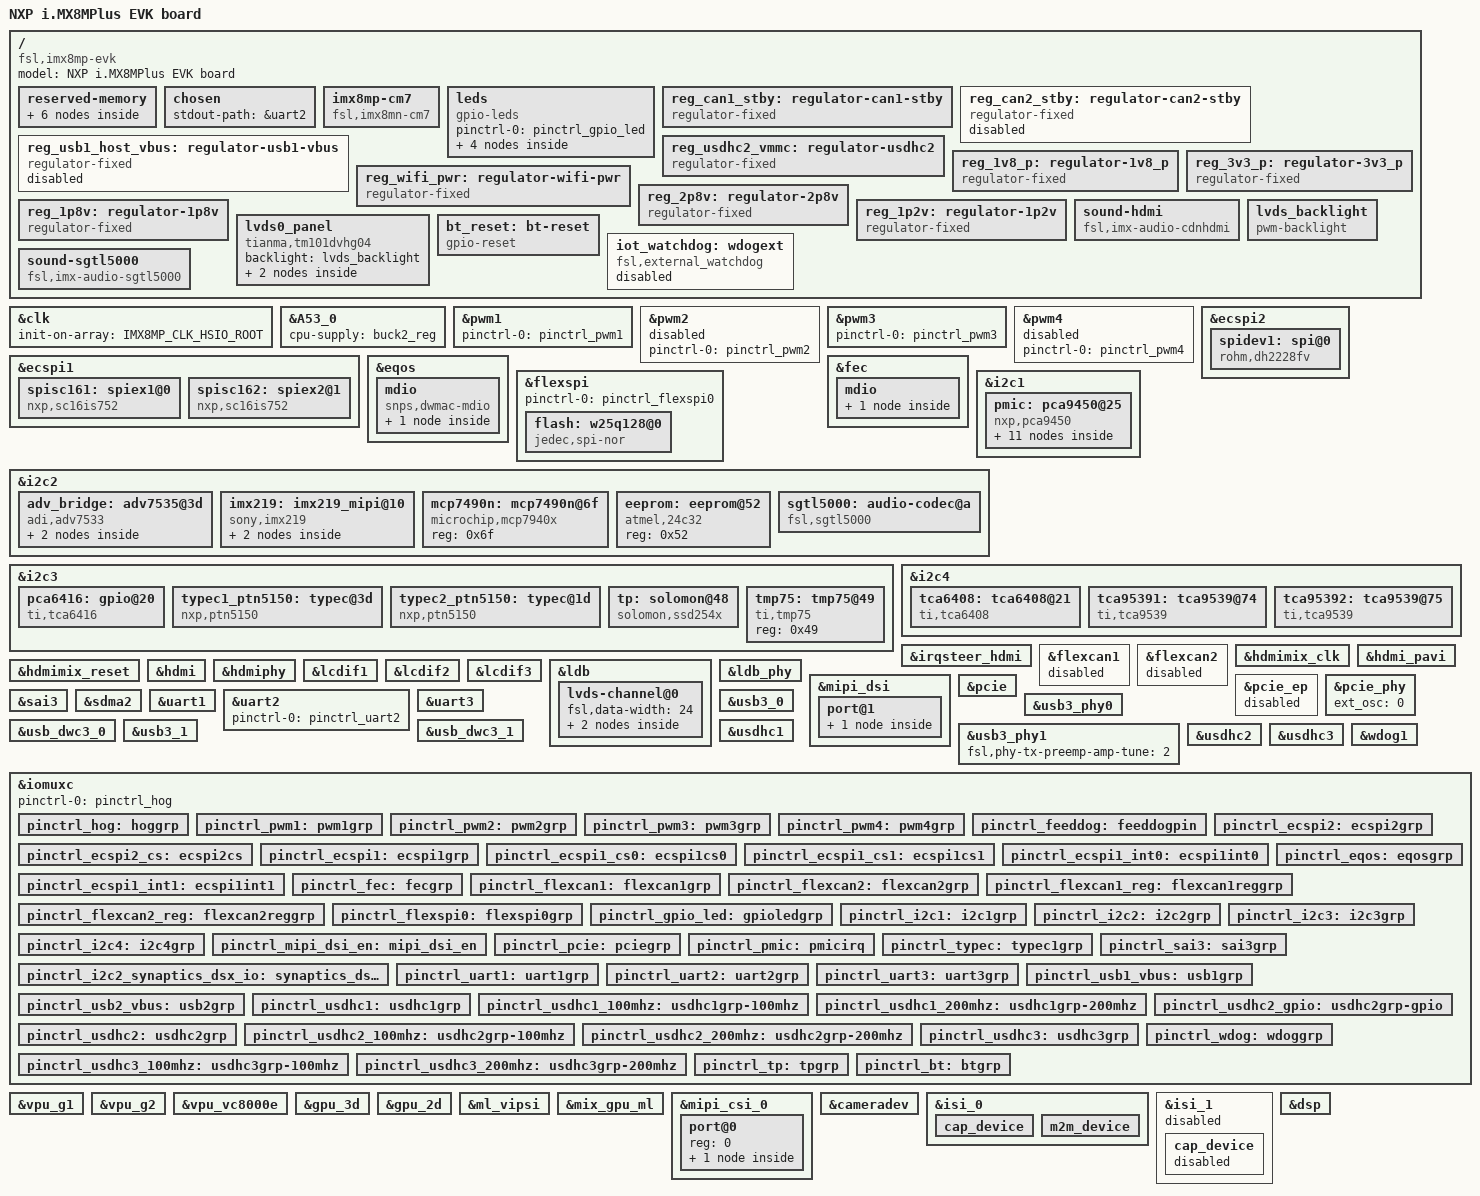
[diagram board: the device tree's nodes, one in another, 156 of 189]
// SPDX-License-Identifier: (GPL-2.0+ OR MIT)
/*
 * Copyright 2019 NXP
 */

/dts-v1/;

#include <dt-bindings/usb/pd.h>
#include "imx8mp-common.dtsi"

/ {
	model = "NXP i.MX8MPlus EVK board";
	compatible = "fsl,imx8mp-evk", "fsl,imx8mp";

	reserved-memory {
		#address-cells = <2>;
		#size-cells = <2>;
		ranges;

		rpmsg_reserved: rpmsg@0x55800000 {
			no-map;
			reg = <0 0x55800000 0 0x800000>;
		};

		m7_reserved: m7@0x80000000 {
			no-map;
			reg = <0 0x80000000 0 0x1000000>;
		};

		vdev0vring0: vdev0vring0@55000000 {
			compatible = "shared-dma-pool";
			reg = <0 0x55000000 0 0x8000>;
			no-map;
		};

		vdev0vring1: vdev0vring1@55008000 {
			compatible = "shared-dma-pool";
			reg = <0 0x55008000 0 0x8000>;
			no-map;
		};

		vdevbuffer: vdevbuffer@55400000 {
			compatible = "shared-dma-pool";
			reg = <0 0x55400000 0 0x100000>;
			no-map;
		};

		rsc-table {
			reg = <0 0x550ff000 0 0x1000>;
			no-map;
		};
	};

	chosen {
		stdout-path = &uart2;
	};

	imx8mp-cm7 {
		compatible = "fsl,imx8mn-cm7";
		rsc-da = <0x55000000>;
		clocks = <&clk IMX8MP_CLK_M7_DIV>;
		mbox-names = "tx", "rx", "rxdb";
		mboxes = <&mu 0 1
			  &mu 1 1
			  &mu 3 1>;
		memory-region = <&vdev0vring0>, <&vdev0vring1>, <&vdevbuffer>;
		status = "okay";
	};

	leds {
		compatible = "gpio-leds";
		pinctrl-names = "default";
		pinctrl-0 = <&pinctrl_gpio_led>;

		status {
			label = "status";
			gpios = <&gpio3 16 GPIO_ACTIVE_HIGH>;
			default-state = "off"; 
		};

		screen-vertical {
			label = "ScreenVertical";
			gpios = <&tca95392 1 GPIO_ACTIVE_LOW>;
			default-state = "on";
		};

		screen-horizontal {
			label = "ScreenHorizontal";
			gpios = <&tca95392 2 GPIO_ACTIVE_HIGH>;
			default-state = "on";
		};

		csi-gpio {
			label = "CSI_GPIO";
			gpios = <&tca95392 11 GPIO_ACTIVE_HIGH>;
			default-state = "on";
		};
	};

	reg_can1_stby: regulator-can1-stby {
		compatible = "regulator-fixed";
		regulator-name = "can1-stby";
		pinctrl-names = "default";
		pinctrl-0 = <&pinctrl_flexcan1_reg>;
		regulator-min-microvolt = <3300000>;
		regulator-max-microvolt = <3300000>;
		gpio = <&gpio5 5 GPIO_ACTIVE_HIGH>;
		enable-active-high;
	};

	reg_can2_stby: regulator-can2-stby {
		compatible = "regulator-fixed";
		regulator-name = "can2-stby";
		pinctrl-names = "default";
		pinctrl-0 = <&pinctrl_flexcan2_reg>;
		regulator-min-microvolt = <3300000>;
		regulator-max-microvolt = <3300000>;
		gpio = <&gpio4 27 GPIO_ACTIVE_HIGH>;
		enable-active-high;
	        status = "disable";
	};

	reg_usb1_host_vbus: regulator-usb1-vbus {
		compatible = "regulator-fixed";
		regulator-name = "usb1_host_vbus";
		pinctrl-names = "default";
		pinctrl-0 = <&pinctrl_usb1_vbus>;
		regulator-min-microvolt = <5000000>;
		regulator-max-microvolt = <5000000>;
		gpio = <&gpio1 14 GPIO_ACTIVE_HIGH>;
		enable-active-high;
		regulator-always-on;
	        status = "disable";
	};

	reg_usdhc2_vmmc: regulator-usdhc2 {
		compatible = "regulator-fixed";
		regulator-name = "VSD_3V3";
		regulator-min-microvolt = <3300000>;
		regulator-max-microvolt = <3300000>;
		gpio = <&gpio2 19 GPIO_ACTIVE_HIGH>;
		enable-active-high;
		startup-delay-us = <100>;
		off-on-delay-us = <12000>;
	};

	reg_1v8_p: regulator-1v8_p {
		compatible = "regulator-fixed";
		regulator-name = "vddd_1v8";
		regulator-min-microvolt = <1800000>;
		regulator-max-microvolt = <1800000>;
	};

	reg_3v3_p: regulator-3v3_p {
		compatible = "regulator-fixed";
		regulator-name = "vddio_vdda_3v3";
 		regulator-min-microvolt = <3300000>;
 		regulator-max-microvolt = <3300000>;
	};

        reg_wifi_pwr: regulator-wifi-pwr {
                compatible = "regulator-fixed";
                regulator-name = "wifi-pwr";
                regulator-min-microvolt = <3300000>;
                regulator-max-microvolt = <3300000>;
                gpio = <&gpio3 24 GPIO_ACTIVE_HIGH>;
                enable-active-high;
                regulator-always-on;
                startup-delay-us = <10000>;
                off-on-delay-us = <12000>;
        };

        reg_2p8v: regulator-2p8v {
                compatible = "regulator-fixed";
                regulator-name = "imx219_vana";
                regulator-min-microvolt = <2800000>;
                regulator-max-microvolt = <2800000>;
        };

        reg_1p8v: regulator-1p8v {
                compatible = "regulator-fixed";
                regulator-name = "imx219_vdig";
                regulator-min-microvolt = <1800000>;
                regulator-max-microvolt = <1800000>;
        };

        reg_1p2v: regulator-1p2v {
                compatible = "regulator-fixed";
                regulator-name = "imx219_vddl";
                regulator-min-microvolt = <1200000>;
                regulator-max-microvolt = <1200000>;
        };

	sound-hdmi {
		compatible = "fsl,imx-audio-cdnhdmi";
		model = "audio-hdmi";
		audio-cpu = <&aud2htx>;
		hdmi-out;
		constraint-rate = <44100>,
				<88200>,
				<176400>,
				<32000>,
				<48000>,
				<96000>,
				<192000>;
		status = "okay";
	};

	lvds_backlight: lvds_backlight {
		compatible = "pwm-backlight";
		pwms = <&pwm1 0 100000>;
		status = "okay";

		brightness-levels = < 0  1  2  3  4  5  6  7  8  9
				     10 11 12 13 14 15 16 17 18 19
				     20 21 22 23 24 25 26 27 28 29
				     30 31 32 33 34 35 36 37 38 39
				     40 41 42 43 44 45 46 47 48 49
				     50 51 52 53 54 55 56 57 58 59
				     60 61 62 63 64 65 66 67 68 69
				     70 71 72 73 74 75 76 77 78 79
				     80 81 82 83 84 85 86 87 88 89
				     90 91 92 93 94 95 96 97 98 99
				    100>;
		default-brightness-level = <80>;
	};

	lvds0_panel {
		compatible = "tianma,tm101dvhg04";
		backlight = <&lvds_backlight>;
		port {
			panel_lvds_in: endpoint {
				remote-endpoint = <&lvds_out>;
			};
		};
	};

	bt_reset: bt-reset {
		compatible = "gpio-reset";
		reset-gpios = <&gpio3 25 GPIO_ACTIVE_LOW>;
		reset-delay-us = <1000>;
		#reset-cells = <0>;
	};

        iot_watchdog: wdogext {
                pinctrl-names = "default";
                pinctrl-0 = <&pinctrl_feeddog>;
                compatible = "fsl,external_watchdog";
                wdt-in = <&gpio1 0 GPIO_ACTIVE_LOW>;
                wdt-feed-interval = <20>;
                //status = "okay";
                status = "disabled";
        };

	sound-sgtl5000 {
		compatible = "fsl,imx-audio-sgtl5000";
		model = "imx6ul-sgtl5000";
		audio-cpu = <&sai3>;
		audio-codec = <&sgtl5000>;
		audio-routing =
			"MIC_IN", "Mic Jack",
			"Mic Jack", "Mic Bias",
			"Headphone Jack", "HP_OUT";
		status = "okay";
	};

};

&clk {
	init-on-array = <IMX8MP_CLK_HSIO_ROOT>;
};

&A53_0 {
	cpu-supply = <&buck2_reg>;
};

&pwm1 {
	pinctrl-names = "default";
	pinctrl-0 = <&pinctrl_pwm1>;
	status = "okay";
};

&pwm2 {
	pinctrl-names = "default";
	pinctrl-0 = <&pinctrl_pwm2>;
	//status = "okay";
	status = "disabled";
};

/* Beeper */
&pwm3 {
        pinctrl-names = "default";
        pinctrl-0 = <&pinctrl_pwm3>;
        status = "okay";
};

&pwm4 {
	pinctrl-names = "default";
	pinctrl-0 = <&pinctrl_pwm4>;
	//status = "okay";
	status = "disabled";
};


&ecspi2 {
	#address-cells = <1>;
	#size-cells = <0>;
	fsl,spi-num-chipselects = <1>;
	pinctrl-names = "default";
	pinctrl-0 = <&pinctrl_ecspi2 &pinctrl_ecspi2_cs>;
	cs-gpios = <&gpio5 13 GPIO_ACTIVE_LOW>;
	status = "okay";

	spidev1: spi@0 {
		reg = <0>;
		compatible = "rohm,dh2228fv";
		spi-max-frequency = <500000>;
	};
};

&ecspi1 {
	#address-cells = <1>;
	#size-cells = <0>;
	fsl,spi-num-chipselects = <2>;
	pinctrl-names = "default";
	pinctrl-0 = <&pinctrl_ecspi1 &pinctrl_ecspi1_cs0 &pinctrl_ecspi1_int0
                     &pinctrl_ecspi1_int1 &pinctrl_ecspi1_cs1>;
	cs-gpios = <&gpio5 9 GPIO_ACTIVE_LOW
                    &gpio1 1 GPIO_ACTIVE_LOW>;
	status = "ok";

	spisc161: spiex1@0 {
		reg = <0>;
		compatible = "nxp,sc16is752";
		interrupt-parent = <&gpio4>;
		interrupts = <0 IRQ_TYPE_EDGE_FALLING>;
                clock-frequency = <14745600>;
		spi-max-frequency = <2000000>;
	};
	spisc162: spiex2@1 {
		reg = <1>;
		compatible = "nxp,sc16is752";
		interrupt-parent = <&gpio4>;
		interrupts = <19 IRQ_TYPE_EDGE_FALLING>;
                clock-frequency = <14745600>;
		spi-max-frequency = <2000000>;
	};
};

&eqos {
	pinctrl-names = "default";
	pinctrl-0 = <&pinctrl_eqos>;
	phy-mode = "rgmii-id";
	phy-handle = <&ethphy0>;
	status = "okay";

	mdio {
		compatible = "snps,dwmac-mdio";
		#address-cells = <1>;
		#size-cells = <0>;

		ethphy0: ethernet-phy@2 {
			compatible = "ethernet-phy-ieee802.3-c22";
			reg = <2>;
			micrel,led-mode = <1>;
                        eee-broken-100tx;
                        eee-broken-1000t;
                        enable-10bt-preamble;
		};
	};
};

&fec {
	pinctrl-names = "default";
	pinctrl-0 = <&pinctrl_fec>;
	phy-mode = "rgmii-id";
	phy-handle = <&ethphy1>;
	fsl,magic-packet;
	status = "okay";

	mdio {
		#address-cells = <1>;
		#size-cells = <0>;

		ethphy1: ethernet-phy@1 {
			compatible = "ethernet-phy-ieee802.3-c22";
			reg = <1>;
			micrel,led-mode = <1>;
                        eee-broken-100tx;
                        eee-broken-1000t;
		};
	};
};

&flexspi {
	pinctrl-names = "default";
	pinctrl-0 = <&pinctrl_flexspi0>;
	status = "okay";

	/*	Winbond 25Q128JWSIQ SPI NOR flash	*/
	flash: w25q128@0 {
		#address-cells = <1>;
		#size-cells = <1>;
		compatible = "jedec,spi-nor";
		m25p,fast-read;
		spi-tx-bus-width = <1>;
		spi-rx-bus-width = <4>;
		spi-max-frequency = <40000000>;
		reg = <0>;
		status = "okay";
	};
};

&i2c1 {
	clock-frequency = <100000>;
	pinctrl-names = "default";
	pinctrl-0 = <&pinctrl_i2c1>;
	status = "okay";

	pmic: pca9450@25 {
		reg = <0x25>;
		compatible = "nxp,pca9450";
		/* PMIC PCA9450 PMIC_nINT GPIO1_IO3 */
		pinctrl-0 = <&pinctrl_pmic>;
		gpio_intr = <&gpio1 3 GPIO_ACTIVE_LOW>;

		regulators {
			#address-cells = <1>;
			#size-cells = <0>;

			pca9450,pmic-buck2-uses-i2c-dvs;
			/* Run/Standby voltage */
			pca9450,pmic-buck2-dvs-voltage = <950000>, <850000>;

			buck1_reg: regulator@0 {
				reg = <0>;
				regulator-compatible = "buck1";
				regulator-min-microvolt = <600000>;
				regulator-max-microvolt = <2187500>;
				regulator-boot-on;
				regulator-always-on;
				regulator-ramp-delay = <3125>;
			};

			buck2_reg: regulator@1 {
				reg = <1>;
				regulator-compatible = "buck2";
				regulator-min-microvolt = <600000>;
				regulator-max-microvolt = <2187500>;
				regulator-boot-on;
				regulator-always-on;
				regulator-ramp-delay = <3125>;
			};

			buck4_reg: regulator@3 {
				reg = <3>;
				regulator-compatible = "buck4";
				regulator-min-microvolt = <600000>;
				regulator-max-microvolt = <3400000>;
				regulator-boot-on;
				regulator-always-on;
			};

			buck5_reg: regulator@4 {
				reg = <4>;
				regulator-compatible = "buck5";
				regulator-min-microvolt = <600000>;
				regulator-max-microvolt = <3400000>;
				regulator-boot-on;
				regulator-always-on;
			};

			buck6_reg: regulator@5 {
				reg = <5>;
				regulator-compatible = "buck6";
				regulator-min-microvolt = <600000>;
				regulator-max-microvolt = <3400000>;
				regulator-boot-on;
				regulator-always-on;
			};

			ldo1_reg: regulator@6 {
				reg = <6>;
				regulator-compatible = "ldo1";
				regulator-min-microvolt = <1600000>;
				regulator-max-microvolt = <3300000>;
				regulator-boot-on;
				regulator-always-on;
			};

			ldo2_reg: regulator@7 {
				reg = <7>;
				regulator-compatible = "ldo2";
				regulator-min-microvolt = <800000>;
				regulator-max-microvolt = <1150000>;
				regulator-boot-on;
				regulator-always-on;
			};

			ldo3_reg: regulator@8 {
				reg = <8>;
				regulator-compatible = "ldo3";
				regulator-min-microvolt = <800000>;
				regulator-max-microvolt = <3300000>;
				regulator-boot-on;
				regulator-always-on;
			};

			ldo4_reg: regulator@9 {
				reg = <9>;
				regulator-compatible = "ldo4";
				regulator-min-microvolt = <800000>;
				regulator-max-microvolt = <3300000>;
				regulator-boot-on;
				regulator-always-on;
			};

			ldo5_reg: regulator@10 {
				reg = <10>;
				regulator-compatible = "ldo5";
				regulator-min-microvolt = <1800000>;
				regulator-max-microvolt = <3300000>;
			};
		};
	};
};


&i2c2 {
	clock-frequency = <100000>;
	pinctrl-names = "default";
	pinctrl-0 = <&pinctrl_i2c2>;
	status = "okay";

	adv_bridge: adv7535@3d {
		compatible = "adi,adv7533";
		reg = <0x3d>;
		adi,addr-cec = <0x3b>;
		adi,dsi-lanes = <4>;
		status = "okay";

		port {
			adv7535_from_dsim: endpoint {
				remote-endpoint = <&dsim_to_adv7535>;
			};
		};
	};

        imx219: imx219_mipi@10 {
		status = "okay";
		compatible = "sony,imx219";
		reg = <0x10>;
		//rotation = <180>;
                clocks = <&clk IMX8MP_CLK_IPP_DO_CLKO2>;
                clock-names = "xclk";
                assigned-clocks = <&clk IMX8MP_CLK_IPP_DO_CLKO2>;
                assigned-clock-parents = <&clk IMX8MP_CLK_24M>;
                assigned-clock-rates = <24000000>;

		VANA-supply = <&reg_2p8v>;      /* 2.8v */
		VDIG-supply = <&reg_1p8v>;   /* 1.8v */
		VDDL-supply = <&reg_1p2v>;   /* 1.2v */

		port {
			imx219_0_ep: endpoint {
				remote-endpoint = <&mipi_csi0_ep>;
				data-lanes = <1 2>;
				clock-lanes = <0>;
				// TBD for below properties
				clock-noncontinuous;
				link-frequencies = /bits/ 64 <456000000>;
			};
		};
	};

	mcp7490n: mcp7490n@6f {
		compatible = "microchip,mcp7940x";
		reg = <0x6f>;
		status = "okay";
	};

	/*	EEPROM CHIP 24AA32A-I/SN	*/
	eeprom: eeprom@52 {
		compatible = "atmel,24c32";
		reg = <0x52>;
		status = "okay";
	};

	sgtl5000: audio-codec@a {
		compatible = "fsl,sgtl5000";
		reg = <0x0a>;
		clocks = <&audiomix_clk IMX8MP_CLK_AUDIOMIX_SAI3_MCLK1>;
		clock-names = "mclk";
		VDDD-supply = <&reg_1v8_p>;
		VDDIO-supply = <&reg_1v8_p>;
		VDDA-supply = <&reg_3v3_p>;
		status = "okay";
	};

};

&i2c3 {
	clock-frequency = <100000>;
	pinctrl-names = "default";
	pinctrl-0 = <&pinctrl_i2c3>;
	status = "okay";

	pca6416: gpio@20 {
		compatible = "ti,tca6416";
		reg = <0x20>;
		gpio-controller;
		#gpio-cells = <2>;
	};

	typec1_ptn5150: typec@3d {
		compatible = "nxp,ptn5150";
		reg = <0x3d>;
                pinctrl-names = "default";
	        pinctrl-0 = <&pinctrl_usb1_vbus>;
		//connect-gpios = <&gpio1 11 GPIO_ACTIVE_HIGH>;
		vbus-gpios = <&gpio1 11 GPIO_ACTIVE_HIGH>;
	};

	typec2_ptn5150: typec@1d {
		compatible = "nxp,ptn5150";
		reg = <0x1d>;
                pinctrl-names = "default";
	        pinctrl-0 = <&pinctrl_usb2_vbus>;
		//connect-gpios = <&gpio1 14 GPIO_ACTIVE_HIGH>;
		vbus-gpios = <&gpio1 14 GPIO_ACTIVE_HIGH>;
	};

	tp: solomon@48 {
		compatible = "solomon,ssd254x";
		pinctrl-names = "default";
		pinctrl-0 = <&pinctrl_tp>;
		reg = <0x48>;
		gpios = <&gpio4 27 1>, /* interrupt */
		<&tca95392 0 1>; /* Reset */
	};

	/*	temperature sensor	*/
	tmp75: tmp75@49 {
		compatible = "ti,tmp75";
		reg = <0x49>;
		status = "okay";
	};
};

&i2c4 {
        clock-frequency = <100000>;
        pinctrl-names = "default";
        pinctrl-0 = <&pinctrl_i2c4>;
        status = "okay";

        tca6408: tca6408@21 {
                compatible = "ti,tca6408";
                reg = <0x21>;
                #gpio-cells = <2>;
                gpio-controller;
        };

        tca95391: tca9539@74 {
                compatible = "ti,tca9539";
                reg = <0x74>;
                #gpio-cells = <2>;
                gpio-controller;
        };

        tca95392: tca9539@75 {
                compatible = "ti,tca9539";
                reg = <0x75>;
                #gpio-cells = <2>;
                gpio-controller;
        };
};

&irqsteer_hdmi {
	status = "okay";
};

&flexcan1 {
	pinctrl-names = "default";
	pinctrl-0 = <&pinctrl_flexcan1>;
	xceiver-supply = <&reg_can1_stby>;
	status = "disabled";
};

&flexcan2 {
	pinctrl-names = "default";
	pinctrl-0 = <&pinctrl_flexcan2>;
	xceiver-supply = <&reg_can2_stby>;
	pinctrl-assert-gpios = <&pca6416 3 GPIO_ACTIVE_HIGH>;
	status = "disabled";/* can2 pin conflict with pdm: gpio low select pdm, gpio high select can2 */
};

&hdmimix_clk {
	status = "okay";
};

&hdmimix_reset {
	status = "okay";
};

&hdmi_pavi {
	status = "okay";
};

&hdmi {
	status = "okay";
};

&hdmiphy {
	status = "okay";
};

&lcdif1 {
	status = "okay";
};

&lcdif2 {
	status = "okay";
};

&lcdif3 {
	status = "okay";

	thres-low  = <1 2>;             /* (FIFO * 1 / 2) */
	thres-high = <3 4>;             /* (FIFO * 3 / 4) */
};

&ldb {
	status = "okay";

	lvds-channel@0 {
		fsl,data-width = <24>;
		status = "okay";

		port@1 {
			reg = <1>;

			lvds_out: endpoint {
				remote-endpoint = <&panel_lvds_in>;
			};
		};
	};
};

&ldb_phy {
	status = "okay";
};

&mipi_dsi {
	status = "okay";

	port@1 {
		dsim_to_adv7535: endpoint {
			remote-endpoint = <&adv7535_from_dsim>;
			attach-bridge;
		};
	};
};

&pcie{
	pinctrl-names = "default";
	pinctrl-0 = <&pinctrl_pcie>;
	disable-gpio = <&gpio4 20 GPIO_ACTIVE_LOW>;
	reset-gpio = <&gpio4 18 GPIO_ACTIVE_LOW>;
	ext_osc = <0>;
	clocks = <&clk IMX8MP_CLK_HSIO_AXI_DIV>,
		 <&clk IMX8MP_CLK_PCIE_AUX>,
		 <&clk IMX8MP_CLK_DUMMY>,
		 <&clk IMX8MP_CLK_PCIE_ROOT>;
	clock-names = "pcie", "pcie_aux", "pcie_phy", "pcie_bus";
	assigned-clocks = <&clk IMX8MP_CLK_HSIO_AXI_SRC>,
			  <&clk IMX8MP_CLK_PCIE_AUX>;
	assigned-clock-rates = <500000000>, <10000000>;
	assigned-clock-parents = <&clk IMX8MP_SYS_PLL2_500M>,
				 <&clk IMX8MP_SYS_PLL2_50M>;
	l1ss-disabled;
	status = "okay";
};

&pcie_ep{
	pinctrl-names = "default";
	pinctrl-0 = <&pinctrl_pcie>;
	ext_osc = <1>;
	clocks = <&clk IMX8MP_CLK_HSIO_AXI_DIV>,
		 <&clk IMX8MP_CLK_PCIE_AUX>,
		 <&clk IMX8MP_CLK_DUMMY>,
		 <&clk IMX8MP_CLK_PCIE_ROOT>;
	clock-names = "pcie", "pcie_aux", "pcie_phy", "pcie_bus";
	assigned-clocks = <&clk IMX8MP_CLK_HSIO_AXI_SRC>,
			  <&clk IMX8MP_CLK_PCIE_AUX>;
	assigned-clock-rates = <500000000>, <10000000>;
	assigned-clock-parents = <&clk IMX8MP_SYS_PLL2_500M>,
				 <&clk IMX8MP_SYS_PLL2_50M>;
	status = "disabled";
};

&pcie_phy{
	ext_osc = <0>;
	status = "okay";
};

&sai3 {
	pinctrl-names = "default";
	pinctrl-0 = <&pinctrl_sai3>;
	assigned-clocks = <&clk IMX8MP_CLK_SAI3>;
	assigned-clock-parents = <&clk IMX8MP_AUDIO_PLL1_OUT>;
	assigned-clock-rates = <12288000>;
	clocks = <&audiomix_clk IMX8MP_CLK_AUDIOMIX_SAI3_IPG>, <&clk IMX8MP_CLK_DUMMY>,
		 <&audiomix_clk IMX8MP_CLK_AUDIOMIX_SAI3_MCLK1>, <&clk IMX8MP_CLK_DUMMY>,
		 <&clk IMX8MP_CLK_DUMMY>;
	clock-names = "bus", "mclk0", "mclk1", "mclk2", "mclk3";
	fsl,sai-mclk-direction-output;
	status = "okay";
};

&sdma2 {
	status = "okay";
};

&uart1 { /* BT */
	pinctrl-names = "default";
	pinctrl-0 = <&pinctrl_uart1
			&pinctrl_bt>;
	assigned-clocks = <&clk IMX8MP_CLK_UART1>;
	assigned-clock-parents = <&clk IMX8MP_SYS_PLL1_80M>;
	fsl,uart-has-rtscts;
	resets = <&bt_reset>;
	status = "okay";
};

&uart2 {
	/* console */
	pinctrl-names = "default";
	pinctrl-0 = <&pinctrl_uart2>;
	status = "okay";
};

&uart3 {
	pinctrl-names = "default";
	pinctrl-0 = <&pinctrl_uart3>;
	assigned-clocks = <&clk IMX8MP_CLK_UART3>;
	assigned-clock-parents = <&clk IMX8MP_SYS_PLL1_80M>;
	fsl,uart-has-rtscts;
	status = "okay";
	//status = "disable";
};

&usb3_phy0 {
	//vbus-power-supply = <&typec1_ptn5150>;
	fsl,phy-tx-vref-tune = <6>;
	fsl,phy-tx-rise-tune = <0>;
	fsl,phy-tx-preemp-amp-tune = <3>;
	fsl,phy-comp-dis-tune = <7>;
	fsl,pcs-tx-deemph-3p5db = <0x21>;
	fsl,phy-pcs-tx-swing-full = <0x7f>;
	status = "okay";
};

&usb3_0 {
	status = "okay";
};

&usb_dwc3_0 {
	//dr_mode = "peripheral";
	dr_mode = "otg";
	extcon = <&typec1_ptn5150>;
	hnp-disable;
	srp-disable;
	adp-disable;
	//usb-role-switch;
	status = "okay";
};

&usb3_phy1 {
	fsl,phy-tx-preemp-amp-tune = <2>;
	status = "okay";
};

&usb3_1 {
	status = "okay";
};

&usb_dwc3_1 {
	//dr_mode = "peripheral";
        dr_mode = "otg";
	extcon = <&typec2_ptn5150>;
        hnp-disable;
        srp-disable;
        adp-disable;
        //usb-role-switch;
        status = "okay";
};

&usdhc1 {
	pinctrl-names = "default", "state_100mhz", "state_200mhz";
	pinctrl-0 = <&pinctrl_usdhc1>;
	pinctrl-1 = <&pinctrl_usdhc1_100mhz>;
	pinctrl-2 = <&pinctrl_usdhc1_200mhz>;
	bus-width = <4>;
        vmmc-supply = <&reg_wifi_pwr>;
	non-removable;
	keep-power-in-suspend;
	enable-sdio-wakeup;
	status = "okay";
};

&usdhc2 {
	pinctrl-names = "default", "state_100mhz", "state_200mhz";
	pinctrl-0 = <&pinctrl_usdhc2>, <&pinctrl_usdhc2_gpio>;
	pinctrl-1 = <&pinctrl_usdhc2_100mhz>, <&pinctrl_usdhc2_gpio>;
	pinctrl-2 = <&pinctrl_usdhc2_200mhz>, <&pinctrl_usdhc2_gpio>;
	cd-gpios = <&gpio2 12 GPIO_ACTIVE_LOW>;
	vmmc-supply = <&reg_usdhc2_vmmc>;
	bus-width = <4>;
	status = "okay";
};

&usdhc3 {
	pinctrl-names = "default", "state_100mhz", "state_200mhz";
	pinctrl-0 = <&pinctrl_usdhc3>;
	pinctrl-1 = <&pinctrl_usdhc3_100mhz>;
	pinctrl-2 = <&pinctrl_usdhc3_200mhz>;
	bus-width = <8>;
	non-removable;
	status = "okay";
};

&wdog1 {
	pinctrl-names = "default";
	pinctrl-0 = <&pinctrl_wdog>;
	fsl,ext-reset-output;
	status = "okay";
};

&iomuxc {
	pinctrl-names = "default";
	pinctrl-0 = <&pinctrl_hog>;

	pinctrl_hog: hoggrp {
		fsl,pins = <
			MX8MP_IOMUXC_HDMI_DDC_SCL__HDMIMIX_HDMI_SCL	0x400001c3
			MX8MP_IOMUXC_HDMI_DDC_SDA__HDMIMIX_HDMI_SDA	0x400001c3
			MX8MP_IOMUXC_HDMI_HPD__HDMIMIX_HDMI_HPD		0x40000019
			MX8MP_IOMUXC_HDMI_CEC__HDMIMIX_HDMI_CEC		0x40000019
		>;
	};

	pinctrl_pwm1: pwm1grp {
		fsl,pins = <
			MX8MP_IOMUXC_GPIO1_IO08__PWM1_OUT	0x116
		>;
	};

	pinctrl_pwm2: pwm2grp {
		fsl,pins = <
			MX8MP_IOMUXC_GPIO1_IO11__PWM2_OUT	0x116
		>;
	};

        pinctrl_pwm3: pwm3grp {
                fsl,pins = <
                        MX8MP_IOMUXC_GPIO1_IO10__PWM3_OUT       0x116
                >;
        };

	pinctrl_pwm4: pwm4grp {
		fsl,pins = <
			MX8MP_IOMUXC_SAI5_RXFS__PWM4_OUT	0x116
		>;
	};

        pinctrl_feeddog: feeddogpin {
                fsl,pins = <
                        MX8MP_IOMUXC_GPIO1_IO00__GPIO1_IO00     0x16
                >;
        };

	pinctrl_ecspi2: ecspi2grp {
		fsl,pins = <
			MX8MP_IOMUXC_ECSPI2_SCLK__ECSPI2_SCLK		0x82
			MX8MP_IOMUXC_ECSPI2_MOSI__ECSPI2_MOSI		0x82
			MX8MP_IOMUXC_ECSPI2_MISO__ECSPI2_MISO		0x82
		>;
	};

	pinctrl_ecspi2_cs: ecspi2cs {
		fsl,pins = <
			MX8MP_IOMUXC_ECSPI2_SS0__GPIO5_IO13		0x40000
		>;
	};


	pinctrl_ecspi1: ecspi1grp {
		fsl,pins = <
			MX8MP_IOMUXC_ECSPI1_SCLK__ECSPI1_SCLK		0x82
			MX8MP_IOMUXC_ECSPI1_MOSI__ECSPI1_MOSI		0x82
			MX8MP_IOMUXC_ECSPI1_MISO__ECSPI1_MISO		0x82
		>;
	};

	pinctrl_ecspi1_cs0: ecspi1cs0 {
		fsl,pins = <
			MX8MP_IOMUXC_ECSPI1_SS0__GPIO5_IO09		0x40000
		>;
	};

	pinctrl_ecspi1_cs1: ecspi1cs1 {
		fsl,pins = <
			MX8MP_IOMUXC_GPIO1_IO01__GPIO1_IO01		0x19
		>;
	};

	pinctrl_ecspi1_int0: ecspi1int0 {
		fsl,pins = <
			MX8MP_IOMUXC_SAI1_RXFS__GPIO4_IO00		0x19
		>;
	};

	pinctrl_ecspi1_int1: ecspi1int1 {
		fsl,pins = <
                        MX8MP_IOMUXC_SAI1_TXD7__GPIO4_IO19	        0x19
		>;
	};

	pinctrl_eqos: eqosgrp {
		fsl,pins = <
			MX8MP_IOMUXC_ENET_MDC__ENET_QOS_MDC	                        0x3
			MX8MP_IOMUXC_ENET_MDIO__ENET_QOS_MDIO	                        0x3
			MX8MP_IOMUXC_ENET_RD0__ENET_QOS_RGMII_RD0	                0x91
			MX8MP_IOMUXC_ENET_RD1__ENET_QOS_RGMII_RD1	                0x91
			MX8MP_IOMUXC_ENET_RD2__ENET_QOS_RGMII_RD2	                0x91
			MX8MP_IOMUXC_ENET_RD3__ENET_QOS_RGMII_RD3	                0x91
			MX8MP_IOMUXC_ENET_RXC__CCM_ENET_QOS_CLOCK_GENERATE_RX_CLK	0x91
			MX8MP_IOMUXC_ENET_RX_CTL__ENET_QOS_RGMII_RX_CTL	                0x91
			MX8MP_IOMUXC_ENET_TD0__ENET_QOS_RGMII_TD0	        	0x91
			MX8MP_IOMUXC_ENET_TD1__ENET_QOS_RGMII_TD1	        	0x91
			MX8MP_IOMUXC_ENET_TD2__ENET_QOS_RGMII_TD2	        	0x91
			MX8MP_IOMUXC_ENET_TD3__ENET_QOS_RGMII_TD3	        	0x91
			MX8MP_IOMUXC_ENET_TX_CTL__ENET_QOS_RGMII_TX_CTL         	0x91
			MX8MP_IOMUXC_ENET_TXC__CCM_ENET_QOS_CLOCK_GENERATE_TX_CLK	0x91
			MX8MP_IOMUXC_SAI2_RXC__GPIO4_IO22		                0x19
		>;
	};

	pinctrl_fec: fecgrp {
		fsl,pins = <
			MX8MP_IOMUXC_SAI1_RXD2__ENET1_MDC		0x3
			MX8MP_IOMUXC_SAI1_RXD3__ENET1_MDIO		0x3
			MX8MP_IOMUXC_SAI1_RXD4__ENET1_RGMII_RD0		0x91
			MX8MP_IOMUXC_SAI1_RXD5__ENET1_RGMII_RD1		0x91
			MX8MP_IOMUXC_SAI1_RXD6__ENET1_RGMII_RD2		0x91
			MX8MP_IOMUXC_SAI1_RXD7__ENET1_RGMII_RD3		0x91
			MX8MP_IOMUXC_SAI1_TXC__ENET1_RGMII_RXC		0x91
			MX8MP_IOMUXC_SAI1_TXFS__ENET1_RGMII_RX_CTL	0x91
			MX8MP_IOMUXC_SAI1_TXD0__ENET1_RGMII_TD0		0x91
			MX8MP_IOMUXC_SAI1_TXD1__ENET1_RGMII_TD1		0x91
			MX8MP_IOMUXC_SAI1_TXD2__ENET1_RGMII_TD2		0x91
			MX8MP_IOMUXC_SAI1_TXD3__ENET1_RGMII_TD3		0x91
			MX8MP_IOMUXC_SAI1_TXD4__ENET1_RGMII_TX_CTL	0x91
			MX8MP_IOMUXC_SAI1_TXD5__ENET1_RGMII_TXC		0x91
			MX8MP_IOMUXC_SAI1_RXD0__GPIO4_IO02		0x19
		>;
	};

	pinctrl_flexcan1: flexcan1grp {
		fsl,pins = <
			MX8MP_IOMUXC_SPDIF_RX__CAN1_RX          0x154
			MX8MP_IOMUXC_SPDIF_TX__CAN1_TX          0x154
		>;
	};

	pinctrl_flexcan2: flexcan2grp {
		fsl,pins = <
			MX8MP_IOMUXC_SAI5_MCLK__CAN2_RX		0x154
			MX8MP_IOMUXC_SAI5_RXD3__CAN2_TX		0x154
		>;
	};

	pinctrl_flexcan1_reg: flexcan1reggrp {
		fsl,pins = <
			MX8MP_IOMUXC_SPDIF_EXT_CLK__GPIO5_IO05	0x154	/* CAN1_STBY */
		>;
	};

	pinctrl_flexcan2_reg: flexcan2reggrp {
		fsl,pins = <
			MX8MP_IOMUXC_SAI2_MCLK__GPIO4_IO27	0x154	/* CAN2_STBY */
		>;
	};

	pinctrl_flexspi0: flexspi0grp {
		fsl,pins = <
			MX8MP_IOMUXC_NAND_ALE__FLEXSPI_A_SCLK		0x1c2
			MX8MP_IOMUXC_NAND_CE0_B__FLEXSPI_A_SS0_B	0x82
			MX8MP_IOMUXC_NAND_DATA00__FLEXSPI_A_DATA00	0x82
			MX8MP_IOMUXC_NAND_DATA01__FLEXSPI_A_DATA01	0x82
			MX8MP_IOMUXC_NAND_DATA02__FLEXSPI_A_DATA02	0x82
			MX8MP_IOMUXC_NAND_DATA03__FLEXSPI_A_DATA03	0x82
		>;
	};

	pinctrl_gpio_led: gpioledgrp {
		fsl,pins = <
			MX8MP_IOMUXC_NAND_READY_B__GPIO3_IO16	0x19
		>;
	};

	pinctrl_i2c1: i2c1grp {
		fsl,pins = <
			MX8MP_IOMUXC_I2C1_SCL__I2C1_SCL		0x400001c3
			MX8MP_IOMUXC_I2C1_SDA__I2C1_SDA		0x400001c3
		>;
	};

	pinctrl_i2c2: i2c2grp {
		fsl,pins = <
			MX8MP_IOMUXC_I2C2_SCL__I2C2_SCL			0x400001c3
			MX8MP_IOMUXC_I2C2_SDA__I2C2_SDA			0x400001c3
		>;
	};

	pinctrl_i2c3: i2c3grp {
		fsl,pins = <
			MX8MP_IOMUXC_I2C3_SCL__I2C3_SCL			0x400001c3
			MX8MP_IOMUXC_I2C3_SDA__I2C3_SDA			0x400001c3
		>;
	};

	pinctrl_i2c4: i2c4grp {
		fsl,pins = <
			MX8MP_IOMUXC_I2C4_SCL__I2C4_SCL			0x400001c3
			MX8MP_IOMUXC_I2C4_SDA__I2C4_SDA			0x400001c3
		>;
	};

	pinctrl_mipi_dsi_en: mipi_dsi_en {
		fsl,pins = <
			MX8MP_IOMUXC_GPIO1_IO08__GPIO1_IO08	0x16
		>;
	};

	pinctrl_pcie: pciegrp {
		fsl,pins = <
			MX8MP_IOMUXC_SAI1_MCLK__GPIO4_IO20		0x41
			MX8MP_IOMUXC_SAI1_TXD6__GPIO4_IO18		0x41
		>;
	};

	pinctrl_pmic: pmicirq {
		fsl,pins = <
			MX8MP_IOMUXC_GPIO1_IO03__GPIO1_IO03	0x41
		>;
	};

	pinctrl_typec: typec1grp {
		fsl,pins = <
			MX8MP_IOMUXC_SAI1_TXD7__GPIO4_IO19	0x1c4
		>;
	};

	pinctrl_sai3: sai3grp {
		fsl,pins = <
			MX8MP_IOMUXC_SAI3_TXFS__AUDIOMIX_SAI3_TX_SYNC	0xd6
			MX8MP_IOMUXC_SAI3_TXC__AUDIOMIX_SAI3_TX_BCLK	0xd6
			MX8MP_IOMUXC_SAI3_RXD__AUDIOMIX_SAI3_RX_DATA00	0xd6
			MX8MP_IOMUXC_SAI3_TXD__AUDIOMIX_SAI3_TX_DATA00	0xd6
			MX8MP_IOMUXC_SAI3_MCLK__AUDIOMIX_SAI3_MCLK	0xd6
		>;
	};

	pinctrl_i2c2_synaptics_dsx_io: synaptics_dsx_iogrp {
		fsl,pins = <
			MX8MP_IOMUXC_GPIO1_IO09__GPIO1_IO09		0x16
		>;
	};

	pinctrl_uart1: uart1grp {
		fsl,pins = <
			MX8MP_IOMUXC_UART1_RXD__UART1_DCE_RX	0x140
			MX8MP_IOMUXC_UART1_TXD__UART1_DCE_TX	0x140
			MX8MP_IOMUXC_UART3_RXD__UART1_DCE_CTS	0x140
			MX8MP_IOMUXC_UART3_TXD__UART1_DCE_RTS	0x140
		>;
	};

	pinctrl_uart2: uart2grp {
		fsl,pins = <
			MX8MP_IOMUXC_UART2_RXD__UART2_DCE_RX	0x49
			MX8MP_IOMUXC_UART2_TXD__UART2_DCE_TX	0x49
		>;
	};

	pinctrl_uart3: uart3grp {
		fsl,pins = <
			MX8MP_IOMUXC_SD1_DATA6__UART3_DCE_TX 	0x49
			MX8MP_IOMUXC_SD1_DATA7__UART3_DCE_RX	0x49
		>;
	};

	pinctrl_usb1_vbus: usb1grp {
		fsl,pins = <
			MX8MP_IOMUXC_GPIO1_IO14__GPIO1_IO14	0x19
		>;
	};
	pinctrl_usb2_vbus: usb2grp {
		fsl,pins = <
			MX8MP_IOMUXC_GPIO1_IO11__GPIO1_IO11	0x19
		>;
	};

	pinctrl_usdhc1: usdhc1grp {
		fsl,pins = <
			MX8MP_IOMUXC_SD1_CLK__USDHC1_CLK	0x190
			MX8MP_IOMUXC_SD1_CMD__USDHC1_CMD	0x1d0
			MX8MP_IOMUXC_SD1_DATA0__USDHC1_DATA0	0x1d0
			MX8MP_IOMUXC_SD1_DATA1__USDHC1_DATA1	0x1d0
			MX8MP_IOMUXC_SD1_DATA2__USDHC1_DATA2	0x1d0
			MX8MP_IOMUXC_SD1_DATA3__USDHC1_DATA3	0x1d0
			MX8MP_IOMUXC_SAI5_RXD3__GPIO3_IO24      0x19
		>;
	};

	pinctrl_usdhc1_100mhz: usdhc1grp-100mhz {
		fsl,pins = <
			MX8MP_IOMUXC_SD1_CLK__USDHC1_CLK	0x194
			MX8MP_IOMUXC_SD1_CMD__USDHC1_CMD	0x1d4
			MX8MP_IOMUXC_SD1_DATA0__USDHC1_DATA0	0x1d4
			MX8MP_IOMUXC_SD1_DATA1__USDHC1_DATA1	0x1d4
			MX8MP_IOMUXC_SD1_DATA2__USDHC1_DATA2	0x1d4
			MX8MP_IOMUXC_SD1_DATA3__USDHC1_DATA3	0x1d4
			MX8MP_IOMUXC_SAI5_RXD3__GPIO3_IO24      0x19
		>;
	};

	pinctrl_usdhc1_200mhz: usdhc1grp-200mhz {
		fsl,pins = <
			MX8MP_IOMUXC_SD1_CLK__USDHC1_CLK	0x194
			MX8MP_IOMUXC_SD1_CMD__USDHC1_CMD	0x1d4
			MX8MP_IOMUXC_SD1_DATA0__USDHC1_DATA0	0x1d4
			MX8MP_IOMUXC_SD1_DATA1__USDHC1_DATA1	0x1d4
			MX8MP_IOMUXC_SD1_DATA2__USDHC1_DATA2	0x1d4
			MX8MP_IOMUXC_SD1_DATA3__USDHC1_DATA3	0x1d4
			MX8MP_IOMUXC_SAI5_RXD3__GPIO3_IO24      0x19
		>;
	};

	pinctrl_usdhc2_gpio: usdhc2grp-gpio {
		fsl,pins = <
			MX8MP_IOMUXC_SD2_CD_B__GPIO2_IO12 	0x1c4
			MX8MP_IOMUXC_SD2_RESET_B__GPIO2_IO19	0x41
		>;
	};

	pinctrl_usdhc2: usdhc2grp {
		fsl,pins = <
			MX8MP_IOMUXC_SD2_CLK__USDHC2_CLK	0x190
			MX8MP_IOMUXC_SD2_CMD__USDHC2_CMD	0x1d0
			MX8MP_IOMUXC_SD2_DATA0__USDHC2_DATA0	0x1d0
			MX8MP_IOMUXC_SD2_DATA1__USDHC2_DATA1	0x1d0
			MX8MP_IOMUXC_SD2_DATA2__USDHC2_DATA2	0x1d0
			MX8MP_IOMUXC_SD2_DATA3__USDHC2_DATA3	0x1d0
			MX8MP_IOMUXC_GPIO1_IO04__USDHC2_VSELECT	0xc1
		>;
	};

	pinctrl_usdhc2_100mhz: usdhc2grp-100mhz {
		fsl,pins = <
			MX8MP_IOMUXC_SD2_CLK__USDHC2_CLK	0x194
			MX8MP_IOMUXC_SD2_CMD__USDHC2_CMD	0x1d4
			MX8MP_IOMUXC_SD2_DATA0__USDHC2_DATA0	0x1d4
			MX8MP_IOMUXC_SD2_DATA1__USDHC2_DATA1	0x1d4
			MX8MP_IOMUXC_SD2_DATA2__USDHC2_DATA2	0x1d4
			MX8MP_IOMUXC_SD2_DATA3__USDHC2_DATA3	0x1d4
			MX8MP_IOMUXC_GPIO1_IO04__USDHC2_VSELECT 0xc1
		>;
	};

	pinctrl_usdhc2_200mhz: usdhc2grp-200mhz {
		fsl,pins = <
			MX8MP_IOMUXC_SD2_CLK__USDHC2_CLK	0x196
			MX8MP_IOMUXC_SD2_CMD__USDHC2_CMD	0x1d6
			MX8MP_IOMUXC_SD2_DATA0__USDHC2_DATA0	0x1d6
			MX8MP_IOMUXC_SD2_DATA1__USDHC2_DATA1	0x1d6
			MX8MP_IOMUXC_SD2_DATA2__USDHC2_DATA2	0x1d6
			MX8MP_IOMUXC_SD2_DATA3__USDHC2_DATA3	0x1d6
			MX8MP_IOMUXC_GPIO1_IO04__USDHC2_VSELECT 0xc1
		>;
	};

	pinctrl_usdhc3: usdhc3grp {
		fsl,pins = <
			MX8MP_IOMUXC_NAND_WE_B__USDHC3_CLK	0x190
			MX8MP_IOMUXC_NAND_WP_B__USDHC3_CMD	0x1d0
			MX8MP_IOMUXC_NAND_DATA04__USDHC3_DATA0	0x1d0
			MX8MP_IOMUXC_NAND_DATA05__USDHC3_DATA1	0x1d0
			MX8MP_IOMUXC_NAND_DATA06__USDHC3_DATA2	0x1d0
			MX8MP_IOMUXC_NAND_DATA07__USDHC3_DATA3	0x1d0
			MX8MP_IOMUXC_NAND_RE_B__USDHC3_DATA4	0x1d0
			MX8MP_IOMUXC_NAND_CE2_B__USDHC3_DATA5	0x1d0
			MX8MP_IOMUXC_NAND_CE3_B__USDHC3_DATA6	0x1d0
			MX8MP_IOMUXC_NAND_CLE__USDHC3_DATA7	0x1d0
			MX8MP_IOMUXC_NAND_CE1_B__USDHC3_STROBE	0x190
		>;
	};

	pinctrl_usdhc3_100mhz: usdhc3grp-100mhz {
		fsl,pins = <
			MX8MP_IOMUXC_NAND_WE_B__USDHC3_CLK	0x194
			MX8MP_IOMUXC_NAND_WP_B__USDHC3_CMD	0x1d4
			MX8MP_IOMUXC_NAND_DATA04__USDHC3_DATA0	0x1d4
			MX8MP_IOMUXC_NAND_DATA05__USDHC3_DATA1	0x1d4
			MX8MP_IOMUXC_NAND_DATA06__USDHC3_DATA2	0x1d4
			MX8MP_IOMUXC_NAND_DATA07__USDHC3_DATA3	0x1d4
			MX8MP_IOMUXC_NAND_RE_B__USDHC3_DATA4	0x1d4
			MX8MP_IOMUXC_NAND_CE2_B__USDHC3_DATA5	0x1d4
			MX8MP_IOMUXC_NAND_CE3_B__USDHC3_DATA6	0x1d4
			MX8MP_IOMUXC_NAND_CLE__USDHC3_DATA7	0x1d4
			MX8MP_IOMUXC_NAND_CE1_B__USDHC3_STROBE	0x194
		>;
	};

	pinctrl_usdhc3_200mhz: usdhc3grp-200mhz {
		fsl,pins = <
			MX8MP_IOMUXC_NAND_WE_B__USDHC3_CLK	0x196
			MX8MP_IOMUXC_NAND_WP_B__USDHC3_CMD	0x1d6
			MX8MP_IOMUXC_NAND_DATA04__USDHC3_DATA0	0x1d6
			MX8MP_IOMUXC_NAND_DATA05__USDHC3_DATA1	0x1d6
			MX8MP_IOMUXC_NAND_DATA06__USDHC3_DATA2	0x1d6
			MX8MP_IOMUXC_NAND_DATA07__USDHC3_DATA3	0x1d6
			MX8MP_IOMUXC_NAND_RE_B__USDHC3_DATA4	0x1d6
			MX8MP_IOMUXC_NAND_CE2_B__USDHC3_DATA5	0x1d6
			MX8MP_IOMUXC_NAND_CE3_B__USDHC3_DATA6	0x1d6
			MX8MP_IOMUXC_NAND_CLE__USDHC3_DATA7	0x1d6
			MX8MP_IOMUXC_NAND_CE1_B__USDHC3_STROBE	0x196
		>;
	};

	pinctrl_wdog: wdoggrp {
		fsl,pins = <
			MX8MP_IOMUXC_GPIO1_IO02__WDOG1_WDOG_B	0xc6
		>;
	};

	pinctrl_tp: tpgrp {
		fsl,pins = <
			MX8MP_IOMUXC_SAI2_MCLK__GPIO4_IO27      0x1c4
		>;
	};

	pinctrl_bt: btgrp {
		fsl,pins = <
			MX8MP_IOMUXC_SAI5_MCLK__GPIO3_IO25        0x19 
		>;
	};
};

&vpu_g1 {
	status = "okay";
};

&vpu_g2 {
	status = "okay";
};

&vpu_vc8000e {
	status = "okay";
};

&gpu_3d {
	status = "okay";
};

&gpu_2d {
	status = "okay";
};

&ml_vipsi {
	status = "okay";
};

&mix_gpu_ml {
	status = "okay";
};

&mipi_csi_0 {
	#address-cells = <1>;
	#size-cells = <0>;
	status = "okay";

	port@0 {
		reg = <0>;
		mipi_csi0_ep: endpoint {
			remote-endpoint = <&imx219_0_ep>;
			data-lanes = <2>;
			csis-hs-settle = <13>;
			csis-clk-settle = <2>;
			csis-wclk;
		};
	};
};

&cameradev {
	status = "okay";
};

&isi_0 {
	status = "okay";

	cap_device {
		status = "okay";
	};

	m2m_device {
		status = "okay";
	};
};

&isi_1 {
	status = "disabled";

	cap_device {
		status = "disabled";
	};
};

&dsp {
	status = "okay";
};
